# PWMSS1_EPWM register map
Vendor: Texas Instruments
Peripheral module from a debugger description file (folder DRA74xP_75xP_76xP_77xP).
Registers are 16-bit, access per field, reset 0x0 unless marked. A register's access mark holds for its fields unless they carry their own. Offsets are as the file gives them; lines under a group give offsets from that group; [hi:lo] are bit positions; {n}, {i} and the like mark numbered series; 'fields as' and 'values as' point back to an identical list; <NAME> marks a mode.

## PWMSS1_EPWM
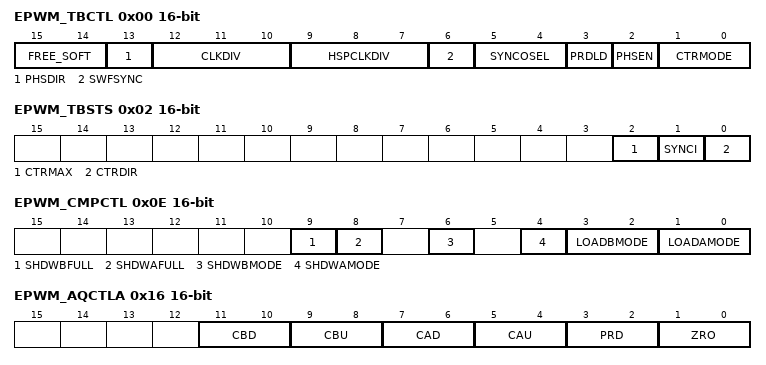
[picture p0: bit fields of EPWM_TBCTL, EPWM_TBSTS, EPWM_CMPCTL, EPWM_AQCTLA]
0x00 EPWM_TBCTL rw
  [15:14] FREE_SOFT — Emulation Mode Bits. These bits select the behavior of the ePWM time-base counter during emulation events: 0x0 = Stop after the next time-base counter increment or decrement 0x1 = Stop when counter completes a whole cycle. (a) Up-count mode: stop when the time-base counter = period ( 0x2 = Free run 0x3 = Free run
  [13] PHSDIR — Phase Direction Bit. This bit is only used when the time-base counter is configured in the up-down-count mode. The PHSDIR bit indicates the direction the time-base counter ( 0x0 = Count down after the synchronization event. 0x1 = Count up after the synchronization event.
  [12:10] CLKDIV — Time-base Clock Prescale Bits. These bits determine part of the time-base clock prescale value. 0x0 = /1 (default on reset) 0x1 = /2 0x2 = /4 0x3 = /8 0x4 = /16 0x5 = /32 0x6 = /64 0x7 = /128
  [9:7] HSPCLKDIV — High-Speed Time-base Clock Prescale Bits. These bits determine part of the time-base clock prescale value. 0x0 = /1 0x1 = /2 (default on reset) 0x2 = /4 0x3 = /6 0x4 = /8 0x5 = /10 0x6 = /12 0x7 = /14
  [6] SWFSYNC — Software Forced Synchronization Pulse. 0x0 = Writing a 0 has no effect and reads always return a 0. 0x1 = Writing a 1 forces a one-time synchronization pulse to be generated. This event is ORed with the EPWMxSYNCI input of the ePWM module. SWFSYNC is valid (operates) only when EPWMxSYNCI is selected by SYNCOSEL = 00.
  [5:4] SYNCOSEL — Synchronization Output Select. These bits select the source of the EPWMxSYNCO signal. 0x0 = EPWMxSYNC: 0x1 = TBCNT = 0: Time-base counter equal to zero ( 0x2 = TBCNT = CMPB : Time-base counter equal to counter-compare B ( 0x3 = Disable EPWMxSYNCO signal
  [3] PRDLD — Active Period Register Load From Shadow Register Select 0x0 = The period register ( 0x1 = Load the
  [2] PHSEN — Counter Register Load From Phase Register Enable 0x0 = Do not load the time-base counter ( 0x1 = Load the time-base counter with the phase register when an EPWMxSYNCI input signal occurs or when a software synchronization is forced by the SWFSYNC bit.
  [1:0] CTRMODE — Counter Mode. The time-base counter mode is normally configured once and not changed during normal operation. If you change the mode of the counter, the change will take effect at the next TBCLK edge and the current counter value shall increment or decrement from the value before the mode change. These bits set the time-base counter mode of operation as follows: 0x0 = Up-count mode 0x1 = Down-count mode 0x2 = Up-down-count mode 0x3 = Stop-freeze counter operation (default on reset)
0x02 EPWM_TBSTS access not given
  [2] CTRMAX — Time-Base Counter Max Latched Status Bit. 0x0 = Reading a 0 indicates the time-base counter never reached its maximum value. Writing a 0 will have no effect. 0x1 = Reading a 1 on this bit indicates that the time-base counter reached the max value 0xFFFF. Writing a 1 to this bit will clear the latched event. (access RW1C)
  [1] SYNCI — Input Synchronization Latched Status Bit. 0x0 = Writing a 0 will have no effect. Reading a 0 indicates no external synchronization event has occurred. 0x1 = Reading a 1 on this bit indicates that an external synchronization event has occurred (EPWMxSYNCI). Writing a 1 to this bit will clear the latched event. (access RW1C)
  [0] CTRDIR ro — Time-Base Counter Direction Status Bit. At reset, the counter is frozen, therefore, this bit has no meaning. To make this bit meaningful, you must first set the appropriate mode via 0x0 = Time-Base Counter is currently counting down. 0x1 = Time-Base Counter is currently counting up.
0x04 HRPWM_TBPHSHR
  [15:8] TBPHSH rw — Time-base phase high-resolution bits
0x06 EPWM_TBPHS rw
  [15:0] TBPHS — These bits set time-base counter phase of the selected ePWM relative to the time-base that is supplying the synchronization input signal. (a) If
0x08 EPWM_TBCNT rw
  [15:0] TBCNT — Reading these bits gives the current time-base counter value. Writing to these bits sets the current time-base counter value. The update happens as soon as the write occurs. The write is NOT synchronized to the time-base clock (TBCLK) and the register is not shadowed.
0x0A EPWM_TBPRD rw
  [15:0] TBPRD — These bits determine the period of the time-base counter. This sets the PWM frequency. Shadowing of this register is enabled and disabled by the
0x0E EPWM_CMPCTL
  [9] SHDWBFULL ro — Counter-compare B ( 0x0 = CMPB shadow FIFO not full yet 0x1 = Indicates the CMPB shadow FIFO is full. A CPU write will overwrite current shadow value.
  [8] SHDWAFULL ro — Counter-compare A ( 0x0 = CMPA shadow FIFO not full yet 0x1 = Indicates the CMPA shadow FIFO is full, a CPU write will overwrite the current shadow value.
  [6] SHDWBMODE rw — Counter-compare B ( 0x0 = Shadow mode. Operates as a double buffer. All writes via the CPU access the shadow register. 0x1 = Immediate mode. Only the active compare B register is used. All writes and reads directly access the active register for immediate compare action.
  [4] SHDWAMODE rw — Counter-compare A ( 0x0 = Shadow mode. Operates as a double buffer. All writes via the CPU access the shadow register. 0x1 = Immediate mode. Only the active compare register is used. All writes and reads directly access the active register for immediate compare action
  [3:2] LOADBMODE rw — Active Counter-Compare B (CMPB) Load From Shadow Select Mode. This bit has no effect in immediate mode ( 0x0 = Load on TBCNT = 0: Time-base counter equal to zero ( 0x1 = Load on TBCNT = PRD: Time-base counter equal to period ( 0x2 = Load on either TBCNT = 0 or TBCNT = PRD 0x3 = Freeze (no loads possible)
  [1:0] LOADAMODE rw — Active Counter-Compare A ( 0x0 = Load on TBCNT = 0: Time-base counter equal to zero ( 0x1 = Load on TBCNT = PRD: Time-base counter equal to period ( 0x2 = Load on either TBCNT = 0 or TBCNT = PRD 0x3 = Freeze (no loads possible)
0x10 HRPWM_CMPAHR reset 0x100
  [15:8] CMPAHR rw — Compare A High-Resolution register bits for MEP step control. A minimum value of 1h is needed to enable HRPWM capabilities. Valid MEP range of operation 1-255h.
0x12 EPWM_CMPA rw
  [15:0] CMPA — The value in the active
0x14 EPWM_CMPB rw
  [15:0] CMPB — The value in the active
0x16 EPWM_AQCTLA
  [11:10] CBD rw — Action when the time-base counter equals the active 0x0 = Do nothing (action disabled) 0x1 = Clear: force EPWMxA output low. 0x2 = Set: force EPWMxA output high. 0x3 = Toggle EPWMxA output: low output signal will be forced high, and a high signal will be forced low.
  [9:8] CBU rw — Action when the counter equals the active 0x0 = Do nothing (action disabled) 0x1 = Clear: force EPWMxA output low. 0x2 = Set: force EPWMxA output high. 0x3 = Toggle EPWMxA output: low output signal will be forced high, and a high signal will be forced low.
  [7:6] CAD rw — Action when the counter equals the active 0x0 = Do nothing (action disabled) 0x1 = Clear: force EPWMxA output low. 0x2 = Set: force EPWMxA output high. 0x3 = Toggle EPWMxA output: low output signal will be forced high, and a high signal will be forced low.
  [5:4] CAU rw — Action when the counter equals the active 0x0 = Do nothing (action disabled) 0x1 = Clear: force EPWMxA output low. 0x2 = Set: force EPWMxA output high. 0x3 = Toggle EPWMxA output: low output signal will be forced high, and a high signal will be forced low.
  [3:2] PRD rw — Action when the counter equals the period. Note: By definition, in count up-down mode when the counter equals period the direction is defined as 0 or counting down. 0x0 = Do nothing (action disabled) 0x1 = Clear: force EPWMxA output low. 0x2 = Set: force EPWMxA output high. 0x3 = Toggle EPWMxA output: low output signal will be forced high, and a high signal will be forced low.
  [1:0] ZRO rw — Action when counter equals zero. Note: By definition, in count up-down mode when the counter equals 0 the direction is defined as 1 or counting up. 0x0 = Do nothing (action disabled) 0x1 = Clear: force EPWMxA output low. 0x2 = Set: force EPWMxA output high. 0x3 = Toggle EPWMxA output: low output signal will be forced high, and a high signal will be forced low.
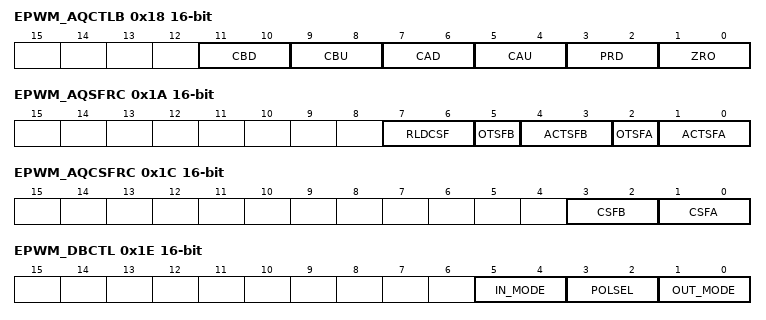
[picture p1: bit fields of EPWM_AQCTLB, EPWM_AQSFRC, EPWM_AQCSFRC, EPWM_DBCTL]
0x18 EPWM_AQCTLB
  [11:10] CBD rw — Action when the counter equals the active 0x0 = Do nothing (action disabled) 0x1 = Clear: force EPWMxB output low. 0x2 = Set: force EPWMxB output high. 0x3 = Toggle EPWMxB output: low output signal will be forced high, and a high signal will be forced low.
  [9:8] CBU rw — Action when the counter equals the active 0x0 = Do nothing (action disabled) 0x1 = Clear: force EPWMxB output low. 0x2 = Set: force EPWMxB output high. 0x3 = Toggle EPWMxB output: low output signal will be forced high, and a high signal will be forced low.
  [7:6] CAD rw — Action when the counter equals the active 0x0 = Do nothing (action disabled) 0x1 = Clear: force EPWMxB output low. 0x2 = Set: force EPWMxB output high. 0x3 = Toggle EPWMxB output: low output signal will be forced high, and a high signal will be forced low.
  [5:4] CAU rw — Action when the counter equals the active 0x0 = Do nothing (action disabled) 0x1 = Clear: force EPWMxB output low. 0x2 = Set: force EPWMxB output high. 0x3 = Toggle EPWMxB output: low output signal will be forced high, and a high signal will be forced low.
  [3:2] PRD rw — Action when the counter equals the period. Note: By definition, in count up-down mode when the counter equals period the direction is defined as 0 or counting down. 0x0 = Do nothing (action disabled) 0x1 = Clear: force EPWMxB output low. 0x2 = Set: force EPWMxB output high. 0x3 = Toggle EPWMxB output: low output signal will be forced high, and a high signal will be forced low.
  [1:0] ZRO rw — Action when counter equals zero. Note: By definition, in count up-down mode when the counter equals 0 the direction is defined as 1 or counting up. 0x0 = Do nothing (action disabled) 0x1 = Clear: force EPWMxB output low. 0x2 = Set: force EPWMxB output high. 0x3 = Toggle EPWMxB output: low output signal will be forced high, and a high signal will be forced low.
0x1A EPWM_AQSFRC
  [7:6] RLDCSF rw — 0x0 = Load on event counter equals zero 0x1 = Load on event counter equals period 0x2 = Load on event counter equals zero or counter equals period 0x3 = Load immediately (the active register is directly accessed by the CPU and is not loaded from the shadow register).
  [5] OTSFB rw — One-Time Software Forced Event on Output B. 0x0 = Writing a 0 (zero) has no effect. Always reads back a 0. This bit is auto cleared once a write to this register is complete, that is, a forced event is initiated. This is a one-shot forced event. It can be overridden by another subsequent event on output B. 0x1 = Initiates a single s/w forced event
  [4:3] ACTSFB rw — Action when One-Time Software Force B Is invoked 0x0 = Does nothing (action disabled) 0x1 = Clear (low) 0x2 = Set (high) 0x3 = Toggle (Low -&gt; High, High -&gt; Low). Note: This action is not qualified by counter direction (CNT_dir)
  [2] OTSFA rw — One-Time Software Forced Event on Output A. 0x0 = Writing a 0 (zero) has no effect. Always reads back a 0. This bit is auto cleared once a write to this register is complete (that is, a forced event is initiated). 0x1 = Initiates a single software forced event.
  [1:0] ACTSFA rw — Action When One-Time Software Force A Is Invoked. 0x0 = Does nothing (action disabled). 0x1 = Clear (low). 0x2 = Set (high). 0x3 = Toggle (Low -&gt; High, High -&gt; Low). Note: This action is not qualified by counter direction (CNT_dir)
0x1C EPWM_AQCSFRC
  [3:2] CSFB rw — Continuous Software Force on Output B. In immediate mode, a continuous force takes effect on the next TBCLK edge. In shadow mode, a continuous force takes effect on the next TBCLK edge after a shadow load into the active register. To configure shadow mode, use 0x0 = Forcing disabled, that is, has no effect 0x1 = Forces a continuous low on output B 0x2 = Forces a continuous high on output B 0x3 = Software forcing is disabled and has no effect
  [1:0] CSFA rw — Continuous Software Force on Output A In immediate mode, a continuous force takes effect on the next TBCLK edge. In shadow mode, a continuous force takes effect on the next TBCLK edge after a shadow load into the active register. 0x0 = Forcing disabled, that is, has no effect 0x1 = Forces a continuous low on output A 0x2 = Forces a continuous high on output A 0x3 = Software forcing is disabled and has no effect
0x1E EPWM_DBCTL
  [5:4] IN_MODE rw — Dead Band Input Mode Control. Bit 5 controls the S5 switch and bit 4 controls the S4 switch. This allows you to select the input source to the falling-edge and rising-edge delay. To produce classical dead-band waveforms, the default is EPWMxA In is the source for both falling and rising-edge delays. 0x0 = EPWMxA In (from the action-qualifier) is the source for both falling-edge and rising-edge delay. 0x1 = EPWMxB In (from the action-qualifier) is the source for rising-edge delayed signal. EPWMxA In (from the action-qualifier) is the source for falling-edge delayed signal. 0x2 = EPWMxA In (from the action-qualifier) is the source for rising-edge delayed signal. EPWMxB In (from the action-qualifier) is the source for falling-edge delayed signal. 0x3 = EPWMxB In (from the action-qualifier) is the source for both rising-edge delay and falling-edge delayed signal.
  [3:2] POLSEL rw — Polarity Select Control. Bit 3 controls the S3 switch and bit 2 controls the S2 switch. This allows you to selectively invert one of the delayed signals before it is sent out of the dead-band submodule. The following descriptions correspond to classical upper/lower switch control as found in one leg of a digital motor control inverter. These assume that 0x0 = Active high (AH) mode. Neither EPWMxA nor EPWMxB is inverted (default). 0x1 = Active low complementary (ALC) mode. EPWMxA is inverted. 0x2 = Active high complementary (AHC). EPWMxB is inverted. 0x3 = Active low (AL) mode. Both EPWMxA and EPWMxB are inverted.
  [1:0] OUT_MODE rw — Dead-band Output Mode Control. Bit 1 controls the S1 switch and bit 0 controls the S0 switch. This allows you to selectively enable or bypass the dead-band generation for the falling-edge and rising-edge delay. 0x0 = Dead-band generation is bypassed for both output signals. In this mode, both the EPWMxA and EPWMxB output signals from the action-qualifier are passed directly to the PWM-chopper submodule. In this mode, the POLSEL and IN_MODE bits have no effect. 0x1 = Disable rising-edge delay. The EPWMxA signal from the action-qualifier is passed straight through to the EPWMxA input of the PWM-chopper submodule. The falling-edge delayed signal is seen on output EPWMxB. The input signal for the delay is determined by 0x2 = Disable falling-edge delay. The EPWMxB signal from the action-qualifier is passed straight through to the EPWMxB input of the PWM-chopper submodule. The rising-edge delayed signal is seen on output EPWMxA. The input signal for the delay is determined by 0x3 = Dead-band is fully enabled for both rising-edge delay on output EPWMxA and falling-edge delay on output EPWMxB. The input signal for the delay is determined by
0x20 EPWM_DBRED
  [9:0] DEL rw — Rising Edge Delay Count. 10 bit counter.
0x22 EPWM_DBFED
  [9:0] DEL rw — Falling Edge Delay Count. 10 bit counter
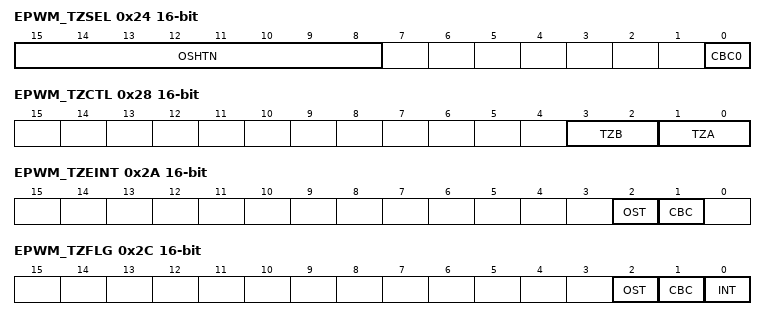
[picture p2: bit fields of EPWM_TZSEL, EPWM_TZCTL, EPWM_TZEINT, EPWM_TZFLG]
0x24 EPWM_TZSEL
  [15:8] OSHTN rw — Trip-zone n (TZn) select. One-Shot (OSHT) trip-zone enable/disable. When any of the enabled pins go low, a one-shot trip event occurs for this ePWM module. When the event occurs, the action defined in the 0x0 = Disable TZn as a one-shot trip source for this ePWM module. 0x1 = Enable TZn as a one-shot trip source for this ePWM module.
  [0] CBC0 rw — Trip-zone 0 (TZ0) select. Cycle-by-Cycle (CBC) trip-zone enable/disable. When any of the enabled pins go low, a cycle-by-cycle trip event occurs for this ePWM module. When the event occurs, the action defined in the 0x0 = Disable TZ0 as a CBC trip source for this ePWM module. 0x1 = Enable TZ0 as a CBC trip source for this ePWM module.
0x28 EPWM_TZCTL
  [3:2] TZB rw — When a trip event occurs the following action is taken on output EPWMxB. Which trip-zone pins can cause an event is defined in the 0x0 = High impedance (EPWMxB = High-impedance state) 0x1 = Force EPWMxB to a high state 0x2 = Force EPWMxB to a low state 0x3 = Do nothing, no action is taken on EPWMxB.
  [1:0] TZA rw — When a trip event occurs the following action is taken on output EPWMxA. Which trip-zone pins can cause an event is defined in the 0x0 = High impedance (EPWMxA = High-impedance state) 0x1 = Force EPWMxA to a high state 0x2 = Force EPWMxA to a low state 0x3 = Do nothing, no action is taken on EPWMxA.
0x2A EPWM_TZEINT
  [2] OST rw — Trip-zone One-Shot Interrupt Enable 0x0 = Disable one-shot interrupt generation 0x1 = Enable Interrupt generation; a one-shot trip event will cause a EPWMxTZINT interrupt.
  [1] CBC rw — Trip-zone Cycle-by-Cycle Interrupt Enable 0x0 = Disable cycle-by-cycle interrupt generation. 0x1 = Enable interrupt generation; a cycle-by-cycle trip event will cause an EPWMxTZINT interrupt.
0x2C EPWM_TZFLG ro
  [2] OST — Latched Status Flag for A One-Shot Trip Event. 0x0 = No one-shot trip event has occurred. 0x1 = Indicates a trip event has occurred on a pin selected as a one-shot trip source. This bit is cleared by writing the appropriate value to the
  [1] CBC — Latched Status Flag for Cycle-By-Cycle Trip Event 0x0 = No cycle-by-cycle trip event has occurred. 0x1 = Indicates a trip event has occurred on a pin selected as a cycle-by-cycle trip source. The
  [0] INT — Latched Trip Interrupt Status Flag 0x0 = Indicates no interrupt has been generated. 0x1 = Indicates an EPWMxTZINT interrupt was generated because of a trip condition. No further EPWMxTZINT interrupts will be generated until this flag is cleared. If the interrupt flag is cleared when either CBC or OST is set, then another interrupt pulse will be generated. Clearing all flag bits will prevent further interrupts. This bit is cleared by writing the appropriate value to the
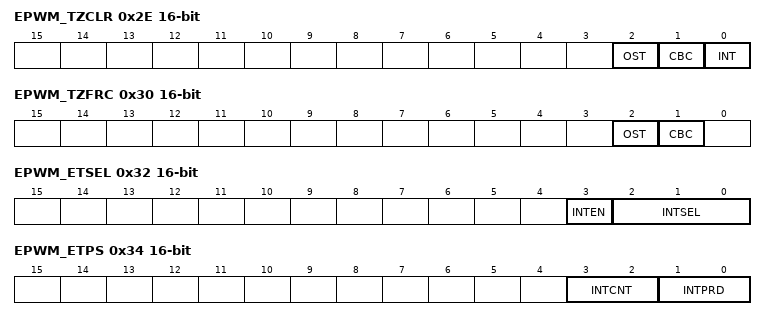
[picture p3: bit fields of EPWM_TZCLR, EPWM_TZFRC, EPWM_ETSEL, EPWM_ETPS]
0x2E EPWM_TZCLR
  [2] OST rw — Clear Flag for One-Shot Trip (OST) Latch 0x0 = Has no effect. Always reads back a 0. 0x1 = Clears this Trip (set) condition.
  [1] CBC rw — Clear Flag for Cycle-By-Cycle (CBC) Trip Latch 0x0 = Has no effect. Always reads back a 0. 0x1 = Clears this Trip (set) condition.
  [0] INT rw — Global Interrupt Clear Flag 0x0 = Has no effect. Always reads back a 0. 0x1 = Clears the trip-interrupt flag for this ePWM module (
0x30 EPWM_TZFRC
  [2] OST rw — Force a One-Shot Trip Event via Software 0x0 = Writing of 0 is ignored. Always reads back a 0. 0x1 = Forces a one-shot trip event and sets the
  [1] CBC rw — Force a Cycle-by-Cycle Trip Event via Software 0x0 = Writing of 0 is ignored. Always reads back a 0. 0x1 = Forces a cycle-by-cycle trip event and sets the
0x32 EPWM_ETSEL
  [3] INTEN rw — Enable ePWM Interrupt (EPWMx_INT) Generation 0x0 = Disable EPWMx_INT generation 0x1 = Enable EPWMx_INT generation
  [2:0] INTSEL rw — ePWM Interrupt (EPWMx_INT) Selection Options 0x0 = Reserved 0x1 = Enable event time-base counter equal to zero. (TBCNT = 0000h) 0x2 = Enable event time-base counter equal to period (TBCNT = TBPRD) 0x3 = Reserved 0x4 = Enable event time-base counter equal to CMPA when the timer is incrementing. 0x5 = Enable event time-base counter equal to CMPA when the timer is decrementing. 0x6 = Enable event: time-base counter equal to CMPB when the timer is incrementing. 0x7 = Enable event: time-base counter equal to CMPB when the timer is decrementing.
0x34 EPWM_ETPS
  [3:2] INTCNT ro — ePWM Interrupt Event (EPWMx_INT) Counter Register. These bits indicate how many selected 0x0 = No events have occurred. 0x1 = 1 event has occurred. 0x2 = 2 events have occurred. 0x3 = 3 events have occurred.
  [1:0] INTPRD rw — ePWM Interrupt (EPWMx_INT) Period Select. These bits determine how many selected 0x0 = Disable the interrupt event counter. No interrupt will be generated and 0x1 = Generate an interrupt on the first event INTCNT = 01 (first event) 0x2 = Generate interrupt on 0x3 = Generate interrupt on
0x36 EPWM_ETFLG ro
  [0] INT — Latched ePWM Interrupt (EPWMx_INT) Status Flag 0x0 = Indicates no event occurred 0x1 = Indicates that an ePWMx interrupt (EWPMx_INT) was generated. No further interrupts will be generated until the flag bit is cleared. Up to one interrupt can be pending while the
0x38 EPWM_ETCLR
  [0] INT rw — ePWM Interrupt (EPWMx_INT) Flag Clear Bit 0x0 = Writing a 0 has no effect. Always reads back a 0. 0x1 = Writing 1 clears the
0x3A EPWM_ETFRC
  [0] INT rw — INT Force Bit. The interrupt will only be generated if the event is enabled in the 0x0 = Writing 0 to this bit will be ignored. Always reads back a 0. 0x1 = Writing 1 generates an interrupt on EPWMxINT and set the INT flag bit. This bit is used for test purposes.
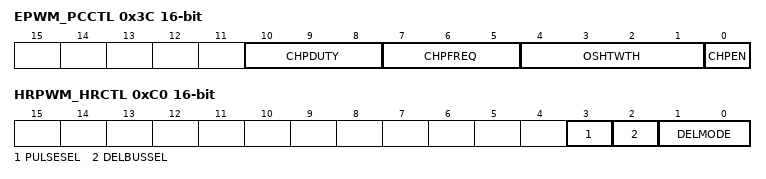
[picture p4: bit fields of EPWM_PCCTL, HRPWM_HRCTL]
0x3C EPWM_PCCTL
  [10:8] CHPDUTY rw — Chopping Clock Duty Cycle 0x0 = Duty = 1/8 (12.5%) 0x1 = Duty = 2/8 (25.0%) 0x2 = Duty = 3/8 (37.5%) 0x3 = Duty = 4/8 (50.0%) 0x4 = Duty = 5/8 (62.5%) 0x5 = Duty = 6/8 (75.0%) 0x6 = Duty = 7/8 (87.5%) 0x7 = Reserved.
  [7:5] CHPFREQ rw — Chopping Clock Frequency 0x0 = Divide by 1 (no prescale). 0x1 = Divide by 2. 0x2 = Divide by 3. 0x3 = Divide by 4. 0x4 = Divide by 5. 0x5 = Divide by 6. 0x6 = Divide by 7. 0x7 = Divide by 8.
  [4:1] OSHTWTH rw — One-Shot Pulse Width 0x0 = 1 - SYSCLKOUT/8 wide 0x1 = 2 - SYSCLKOUT/8 wide 0x2 = 3 - SYSCLKOUT/8 wide 0x3 = 4 - SYSCLKOUT/8 wide 0xF = 16 - SYSCLKOUT/8 wide
  [0] CHPEN rw — PWM-chopping Enable 0x0 = Disable (bypass) PWM chopping function 0x1 = Enable chopping function
0xC0 HRPWM_HRCTL
  [3] PULSESEL rw — Pulse select bits. Selects which pulse to use for timing events in the HRPWM module. Note: The user needs to select the pulse to match the selection in the EPWM module. If TBPHSHR bus is selected, then CNT_zero pulse should be used. If COMPAHR bus is selected, then it should match the bit setting of the 0x0 = Select CNT_zero pulse 0x1 = Select PRD_eq pulse
  [2] DELBUSSEL rw — Delay Bus Select Bit: Selects which bus is used to select the delay for the PWM pulse. 0x0 = Select CMPAHR(8) bus from compare module of EPWM (default on reset). 0x1 = Select TBPHSHR(8) bus from time base module.
  [1:0] DELMODE rw — Delay Mode Bits: Selects which edge of the PWM pulse the delay is inserted. Note: When DELMODE = 0b00, the HRCALM[CALMODE] bits are ignored and the delay line is in by-pass mode. Additionally, DLYIN is connected to CALIN and a continuous low value is fed to the delay line to minimize activity in the module. 0x0 = No delay inserted (default on reset) 0x1 = Delay inserted rising edge 0x2 = Delay inserted falling edge 0x3 = Delay inserted on both edges
